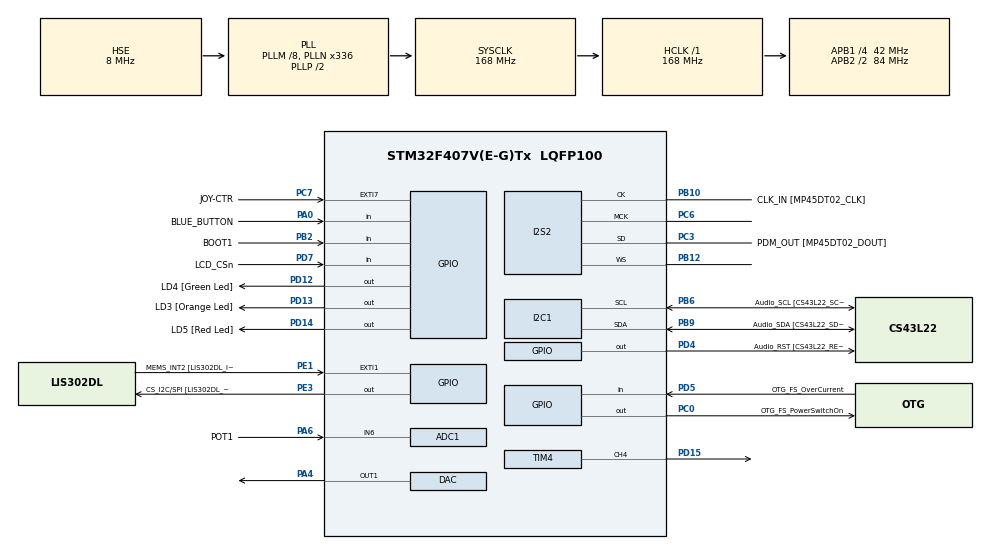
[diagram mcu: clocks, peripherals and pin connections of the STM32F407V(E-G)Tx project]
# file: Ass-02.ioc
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PA11.GPIO_Speed=GPIO_SPEED_FREQ_LOW
PD12.GPIO_Label=LD4 [Green Led]
PH0-OSC_IN.Signal=RCC_OSC_IN
PC10.GPIO_PuPd=GPIO_NOPULL
PB10.GPIO_PuPd=GPIO_NOPULL
PB10.Mode=Half_Duplex_Master
PA10.GPIO_PuPd=GPIO_NOPULL
I2S2.AudioFreqCustom=8192
PC12.Signal=I2S3_SD
PA14.GPIO_Label=SWCLK
PA6.GPIO_Label=POT1
PB6.GPIO_Label=Audio_SCL [CS43L22_SCL]
PC15-OSC32_OUT.GPIO_Label=PC15-OSC32_OUT
PC3.GPIO_Speed=GPIO_SPEED_FREQ_LOW
RCC.SYSCLKSource=RCC_SYSCLKSOURCE_PLLCLK
PD14.GPIO_Speed=GPIO_SPEED_FREQ_LOW
PD7.GPIO_PuPd=GPIO_PULLUP
Dma.DAC1.0.PeriphInc=DMA_PINC_DISABLE
RCC.APB2TimFreq_Value=168000000
PD4.Signal=GPIO_Output
PB6.Signal=I2C1_SCL
PC7.Signal=GPXTI7
PB6.Mode=I2C
PC3.Signal=I2S2_SD
PE1.Signal=GPXTI1
Dma.DAC1.0.Direction=DMA_MEMORY_TO_PERIPH
PB2.Signal=GPIO_Input
DAC.DAC_Trigger=DAC_TRIGGER_T2_TRGO
PA5.GPIO_PuPd=GPIO_NOPULL
PD5.GPIO_Mode=GPIO_MODE_INPUT
PD14.GPIO_PuPd=GPIO_NOPULL
TIM4.Period=100-1
PB2.GPIO_PuPd=GPIO_NOPULL
ADC1.SamplingTime-0\#ChannelRegularConversion=ADC_SAMPLETIME_3CYCLES
Dma.SPI2_TX.1.FIFOMode=DMA_FIFOMODE_ENABLE
Mcu.Package=LQFP100
PB9.Signal=I2C1_SDA
TIM2.Prescaler=84-1
Dma.DAC1.0.PeriphDataAlignment=DMA_PDATAALIGN_HALFWORD
PD12.Signal=GPIO_Output
PA10.Signal=USB_OTG_FS_ID
PB9.GPIO_PuPd=GPIO_NOPULL
Dma.SPI2_TX.1.Instance=DMA1_Stream4
RCC.APB2CLKDivider=RCC_HCLK_DIV2
RCC.APB1TimFreq_Value=84000000
PC12.GPIO_PuPd=GPIO_NOPULL
PA12.GPIO_PuPd=GPIO_NOPULL
TIM4.Channel-PWM\ Generation4\ CH4=TIM_CHANNEL_4
PD15.Signal=S_TIM4_CH4
PC0.PinState=GPIO_PIN_SET
Dma.SPI2_TX.1.MemInc=DMA_MINC_ENABLE
I2S2.AudioFreq=AudioFreqCustomValue
ADC1.Rank-0\#ChannelRegularConversion=1
TIM3.AutoReloadPreload=TIM_AUTORELOAD_PRELOAD_DISABLE
SH.ADCx_IN6.0=ADC1_IN6,IN6
PA9.GPIO_Label=VBUS_FS
PB6.GPIO_PuPd=GPIO_NOPULL
PC6.Signal=I2S2_MCK
PD7.Signal=GPIO_Input
PA11.GPIO_Label=OTG_FS_DM
PE1.GPIO_PuPd=GPIO_NOPULL
TIM4.TIM_MasterSlaveMode=TIM_MASTERSLAVEMODE_ENABLE
PC0.Signal=GPIO_Output
RCC.APB1CLKDivider=RCC_HCLK_DIV4
PC14-OSC32_IN.Signal=RCC_OSC32_IN
PA0-WKUP.GPIO_Label=BLUE_BUTTON
PA0-WKUP.Signal=GPIO_Input
Dma.DAC1.0.MemDataAlignment=DMA_MDATAALIGN_HALFWORD
PC10.GPIO_Mode=GPIO_MODE_AF_PP
PB10.GPIO_Mode=GPIO_MODE_AF_PP
PC6.Mode=Master_Clock_Activated
PA9.Signal=USB_OTG_FS_VBUS
I2S2.VirtualMode=I2S_MODE_MASTER
PC7.GPIO_PuPd=GPIO_PULLUP
PB10.Signal=I2S2_CK
PA5.Signal=SPI1_SCK
PE1.GPIO_Label=MEMS_INT2 [LIS302DL_INT2]
PA7.GPIO_Speed=GPIO_SPEED_FREQ_LOW
NVIC.TIM3_IRQn=true\:0\:0\:false\:false\:true\:true\:true
PB2.GPIO_Mode=GPIO_MODE_INPUT
Dma.SPI2_TX.1.PeriphDataAlignment=DMA_PDATAALIGN_HALFWORD
Dma.SPI2_TX.1.Priority=DMA_PRIORITY_LOW
PD4.GPIO_Speed=GPIO_SPEED_FREQ_LOW
PE3.GPIO_PuPd=GPIO_NOPULL
PH1-OSC_OUT.GPIO_Label=PH1-OSC_OUT
TIM2.Period=125-1
PA13.Mode=Serial_Wire
I2S2.FullDuplexMode=I2S_FULLDUPLEXMODE_DISABLE
Dma.SPI2_TX.1.PeriphBurst=DMA_PBURST_SINGLE
PC7.GPIO_Label=JOY-CTR
PA4.Signal=COMP_DAC1_group
PC12.GPIO_Mode=GPIO_MODE_AF_PP
ADC1.master=1
PA5.GPIO_Label=SPI1_SCK [LIS302DL_SCL/SPC]
PE3.GPIO_Speed=GPIO_SPEED_FREQ_LOW
PC12.GPIO_Label=I2S3_SD [CS43L22_SDIN]
PA11.Signal=USB_OTG_FS_DM
ProjectManager.HeapSize=0x2000
VP_TIM4_VS_ClockSourceINT.Mode=Internal
NVIC.PriorityGroup=NVIC_PRIORITYGROUP_4
PE3.Signal=GPIO_Output
PC3.GPIO_Label=PDM_OUT [MP45DT02_DOUT]
PA0-WKUP.GPIO_PuPd=GPIO_PULLDOWN
PB6.GPIO_Speed=GPIO_SPEED_FREQ_LOW
Dma.SPI2_TX.1.MemDataAlignment=DMA_MDATAALIGN_HALFWORD
Mcu.Family=STM32F4
PC3.Mode=Half_Duplex_Master
PC3.GPIO_Mode=GPIO_MODE_AF_PP
Dma.SPI2_TX.1.MemBurst=DMA_MBURST_SINGLE
RCC.CortexFreq_Value=168000000
PB10.GPIO_Speed=GPIO_SPEED_FREQ_LOW
PB6.GPIO_Mode=GPIO_MODE_AF_OD
PC10.Signal=I2S3_CK
PA7.GPIO_Mode=GPIO_MODE_AF_PP
Dma.SPI2_TX.1.PeriphInc=DMA_PINC_DISABLE
PC0.GPIO_Label=OTG_FS_PowerSwitchOn
PC10.GPIO_Speed=GPIO_SPEED_FREQ_LOW
PA11.GPIO_PuPd=GPIO_NOPULL
NVIC.DMA1_Stream4_IRQn=true\:0\:0\:false\:false\:true\:false\:true
ProjectManager.StackSize=0x4000
PD13.Signal=GPIO_Output
PA12.Signal=USB_OTG_FS_DP
RCC.HCLKFreq_Value=168000000
ADC1.Resolution=ADC_RESOLUTION_8B
TIM3.Period=50
RCC.AHBFreq_Value=168000000
PH0-OSC_IN.Mode=HSE-External-Oscillator
PH0-OSC_IN.GPIO_Label=PH0-OSC_IN
PA9.GPIO_Mode=GPIO_MODE_INPUT
Dma.SPI2_TX.1.FIFOThreshold=DMA_FIFO_THRESHOLD_HALFFULL
ADC1.Channel-0\#ChannelRegularConversion=ADC_CHANNEL_6
RCC.HSE_VALUE=8000000
Dma.DAC1.0.Priority=DMA_PRIORITY_LOW
PC14-OSC32_IN.Mode=LSE-External-Oscillator
Dma.DAC1.0.FIFOMode=DMA_FIFOMODE_DISABLE
PA14.Mode=Serial_Wire
TIM3.Prescaler=16800-1
PA10.GPIO_Label=OTG_FS_ID
PD7.GPIO_Label=LCD_CSn
PH1-OSC_OUT.Mode=HSE-External-Oscillator
PD13.GPIO_Label=LD3 [Orange Led]
PC7.GPIO_ModeDefaultEXTI=GPIO_MODE_IT_FALLING
PA6.Signal=ADCx_IN6
PB12.Mode=Half_Duplex_Master
Dma.SPI2_TX.1.Mode=DMA_CIRCULAR
PD5.GPIO_Label=OTG_FS_OverCurrent
Dma.DAC1.0.Mode=DMA_CIRCULAR
PA10.GPIO_Speed=GPIO_SPEED_FREQ_LOW
TIM2.TIM_MasterOutputTrigger=TIM_TRGO_UPDATE
PB9.GPIO_Speed=GPIO_SPEED_FREQ_LOW
Dma.Request1=SPI2_TX
PC14-OSC32_IN.GPIO_Label=PC14-OSC32_IN
PC0.GPIO_PuPd=GPIO_NOPULL
Dma.Request0=DAC1
VP_TIM3_VS_ClockSourceINT.Mode=Internal
PA12.GPIO_Speed=GPIO_SPEED_FREQ_LOW
RCC.PLLSourceVirtual=RCC_PLLSOURCE_HSE
SH.COMP_DAC1_group.0=DAC_OUT1,DAC_OUT1
PC15-OSC32_OUT.Mode=LSE-External-Oscillator
TIM4.AutoReloadPreload=TIM_AUTORELOAD_PRELOAD_DISABLE
PD12.GPIO_Speed=GPIO_SPEED_FREQ_LOW
Dma.DAC1.0.Instance=DMA1_Stream5
I2S2.Instance=SPI$Index
PB9.GPIO_Label=Audio_SDA [CS43L22_SDA]
PC10.GPIO_Label=I2S3_SCK [CS43L22_SCLK]
SH.S_TIM4_CH4.0=TIM4_CH4,PWM Generation4 CH4
PD5.Signal=GPIO_Input
PE1.GPIO_ModeDefaultEXTI=GPIO_MODE_EVT_RISING
PA9.GPIO_PuPd=GPIO_NOPULL
PA12.GPIO_Label=OTG_FS_DP
PA10.GPIO_Mode=GPIO_MODE_AF_PP
PA13.Signal=SYS_JTMS-SWDIO
PD4.GPIO_PuPd=GPIO_NOPULL
PC0.GPIO_Speed=GPIO_SPEED_FREQ_LOW
ProjectManager.TargetToolchain=SW4STM32
PB10.GPIO_Label=CLK_IN [MP45DT02_CLK]
NVIC.DMA1_Stream5_IRQn=true\:0\:0\:false\:false\:true\:false\:true
PB9.Mode=I2C
TIM4.Prescaler=84-1
PC15-OSC32_OUT.Signal=RCC_OSC32_OUT
PA7.GPIO_PuPd=GPIO_NOPULL
board=STM32F407G-DISC1
PD13.GPIO_Speed=GPIO_SPEED_FREQ_LOW
Dma.SPI2_TX.1.Direction=DMA_MEMORY_TO_PERIPH
RCC.VCOOutputFreq_Value=336000000
PB9.GPIO_Mode=GPIO_MODE_AF_OD
PA12.GPIO_Mode=GPIO_MODE_AF_PP
RCC.APB2Freq_Value=84000000
VP_TIM2_VS_ClockSourceINT.Mode=Internal
PD4.GPIO_Label=Audio_RST [CS43L22_RESET]
PH1-OSC_OUT.Signal=RCC_OSC_OUT
PD13.GPIO_PuPd=GPIO_NOPULL
PD5.GPIO_PuPd=GPIO_NOPULL
PD14.GPIO_Label=LD5 [Red Led]
Mcu.Name=STM32F407V(E-G)Tx
PA13.GPIO_Label=SWDIO
PD14.Signal=GPIO_Output
RCC.48MHZClocksFreq_Value=48000000
RCC.SYSCLKFreq_VALUE=168000000
PA7.GPIO_Label=SPI1_MOSI [LIS302DL_SDA/SDI/SDO]
Dma.DAC1.0.MemInc=DMA_MINC_ENABLE
I2S2.ErrorAudioFreq=-0.27 %
TIM3.TIM_MasterSlaveMode=TIM_MASTERSLAVEMODE_DISABLE
NVIC.EXTI9_5_IRQn=true\:0\:0\:false\:false\:true\:true\:true
PA14.Signal=SYS_JTCK-SWCLK
PB2.GPIO_Label=BOOT1
RCC.HSI_VALUE=16000000
PA5.GPIO_Speed=GPIO_SPEED_FREQ_LOW
RCC.PLLQ=7
ADC1.NbrOfConversionFlag=1
RCC.PLLM=8
RCC.PLLN=336
PE3.GPIO_Label=CS_I2C/SPI [LIS302DL_CS_I2C/SPI]
PA11.GPIO_Mode=GPIO_MODE_AF_PP
RCC.APB1Freq_Value=42000000
PA5.GPIO_Mode=GPIO_MODE_AF_PP
PC12.GPIO_Speed=GPIO_SPEED_FREQ_LOW
I2S2.RealAudioFreq=7.978 KHz
PB12.Signal=I2S2_WS
PC3.GPIO_PuPd=GPIO_NOPULL
PD12.GPIO_PuPd=GPIO_NOPULL
PA7.Signal=SPI1_MOSI

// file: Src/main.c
/* USER CODE BEGIN Header */
/**
  ******************************************************************************
  * @file           : main.c
  * @brief          : Main program body
  ******************************************************************************
  * @attention
  *
  * <h2><center>&copy; Copyright (c) 2020 STMicroelectronics.
  * All rights reserved.</center></h2>
  *
  * This software component is licensed by ST under Ultimate Liberty license
  * SLA0044, the "License"; You may not use this file except in compliance with
  * the License. You may obtain a copy of the License at:
  *                             www.st.com/SLA0044
  *
  ******************************************************************************
  */
/* USER CODE END Header */

#include "main.h"
#include "adc.h"
#include "dac.h"
#include "dma.h"
#include "i2c.h"
#include "i2s.h"
#include "tim.h"
#include "gpio.h"

/* USER CODE BEGIN Includes */

// STEPIEN: Lab Exercise include
#include "Ass-02.h"

/* USER CODE END Includes */

void SystemClock_Config(void);

int main(void)
{
  /* USER CODE BEGIN 1 */

  // STEPIEN: To allow printing to console
  initialise_monitor_handles ();

  /* USER CODE END 1 */

  /* MCU Configuration--------------------------------------------------------*/

  /* Reset of all peripherals, Initializes the Flash interface and the Systick. */
  HAL_Init();

  /* Configure the system clock */
  SystemClock_Config();

  /* Initialize all configured peripherals */
  MX_GPIO_Init();
  MX_DMA_Init();
  MX_ADC1_Init();
  MX_TIM3_Init();
  MX_DAC_Init();
  MX_TIM4_Init();
  MX_I2C1_Init();
  MX_I2S2_Init();
  MX_TIM2_Init();
  /* USER CODE BEGIN 2 */
  // STEPIEN: Call the user code (never returns)
  //
  Ass_02_main();

  /* USER CODE END 2 */

  /* Infinite loop */
  while (1)
  {

  }
}

void SystemClock_Config(void)
{
  RCC_OscInitTypeDef RCC_OscInitStruct = {0};
  RCC_ClkInitTypeDef RCC_ClkInitStruct = {0};
  RCC_PeriphCLKInitTypeDef PeriphClkInitStruct = {0};

  /** Configure the main internal regulator output voltage
  */
  __HAL_RCC_PWR_CLK_ENABLE();
  __HAL_PWR_VOLTAGESCALING_CONFIG(PWR_REGULATOR_VOLTAGE_SCALE1);
  /** Initializes the CPU, AHB and APB busses clocks
  */
  RCC_OscInitStruct.OscillatorType = RCC_OSCILLATORTYPE_HSE;
  RCC_OscInitStruct.HSEState = RCC_HSE_ON;
  RCC_OscInitStruct.PLL.PLLState = RCC_PLL_ON;
  RCC_OscInitStruct.PLL.PLLSource = RCC_PLLSOURCE_HSE;
  RCC_OscInitStruct.PLL.PLLM = 8;
  RCC_OscInitStruct.PLL.PLLN = 336;
  RCC_OscInitStruct.PLL.PLLP = RCC_PLLP_DIV2;
  RCC_OscInitStruct.PLL.PLLQ = 7;
  if (HAL_RCC_OscConfig(&RCC_OscInitStruct) != HAL_OK)
  {
    Error_Handler();
  }
  /** Initializes the CPU, AHB and APB busses clocks
  */
  RCC_ClkInitStruct.ClockType = RCC_CLOCKTYPE_HCLK|RCC_CLOCKTYPE_SYSCLK
                              |RCC_CLOCKTYPE_PCLK1|RCC_CLOCKTYPE_PCLK2;
  RCC_ClkInitStruct.SYSCLKSource = RCC_SYSCLKSOURCE_PLLCLK;
  RCC_ClkInitStruct.AHBCLKDivider = RCC_SYSCLK_DIV1;
  RCC_ClkInitStruct.APB1CLKDivider = RCC_HCLK_DIV4;
  RCC_ClkInitStruct.APB2CLKDivider = RCC_HCLK_DIV2;

  if (HAL_RCC_ClockConfig(&RCC_ClkInitStruct, FLASH_LATENCY_5) != HAL_OK)
  {
    Error_Handler();
  }
  PeriphClkInitStruct.PeriphClockSelection = RCC_PERIPHCLK_I2S;
  PeriphClkInitStruct.PLLI2S.PLLI2SN = 192;
  PeriphClkInitStruct.PLLI2S.PLLI2SR = 2;
  if (HAL_RCCEx_PeriphCLKConfig(&PeriphClkInitStruct) != HAL_OK)
  {
    Error_Handler();
  }
}

void Error_Handler(void)
{
}

/************************ (C) COPYRIGHT STMicroelectronics *****END OF FILE****/
